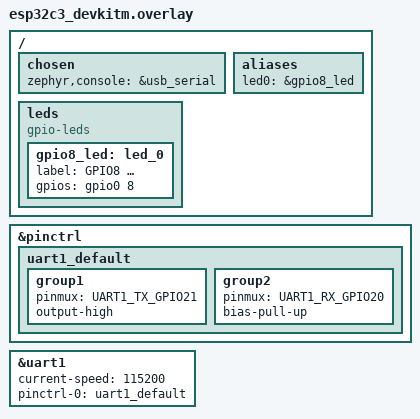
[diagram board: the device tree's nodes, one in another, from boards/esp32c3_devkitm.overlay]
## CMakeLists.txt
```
# SPDX-License-Identifier: Apache-2.0

cmake_minimum_required(VERSION 3.20.0)
find_package(Zephyr REQUIRED HINTS $ENV{ZEPHYR_BASE})
project(esp32_c3_gpio8_blinky)

target_sources(app PRIVATE
	src/main.c
)
```

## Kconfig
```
source "Kconfig.zephyr"

menu "ESP32-C3 OTA demo options"

config APP_BLINK_INTERVAL_MS
	int "GPIO8 blink interval in milliseconds"
	default 1000
	help
	  GPIO8 blink interval used to distinguish the factory image from the
	  OTA-updated application image.

endmenu
```

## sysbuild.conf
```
# Enable MCUboot so sysbuild produces a bootloader image and a signed application.
SB_CONFIG_BOOTLOADER_MCUBOOT=y
```

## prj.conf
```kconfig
# ESP32-C3-DevKitM 的 GPIO8 LED 闪灯配置。
CONFIG_GPIO=y

# 保持开发板默认 UART0 控制台可用，用于启动日志和 OTA 调试。
CONFIG_SERIAL=y
CONFIG_CONSOLE=y
CONFIG_UART_CONSOLE=y

CONFIG_LOG=y
CONFIG_LOG_MODE_IMMEDIATE=y
CONFIG_LOG_BACKEND_UART=y
CONFIG_LOG_DEFAULT_LEVEL=3

# 业务图片流使用独立 UART1，日志继续走 USB Serial/JTAG，避免污染 JPGU 数据。
CONFIG_UART_INTERRUPT_DRIVEN=y
CONFIG_RING_BUFFER=y

# BLE 外设同时提供小程序图片透传服务和 Zephyr MCUmgr/SMP OTA 服务。
CONFIG_BT=y
CONFIG_BT_PERIPHERAL=y
CONFIG_BT_DEVICE_NAME="E-Badge-C3"
CONFIG_BT_MAX_CONN=1
CONFIG_BT_L2CAP_TX_MTU=247
CONFIG_BT_BUF_ACL_RX_SIZE=251
CONFIG_BT_BUF_ACL_TX_SIZE=251
CONFIG_BT_BUF_ACL_TX_COUNT=12
CONFIG_BT_CONN_TX_MAX=12
CONFIG_BT_ATT_PREPARE_COUNT=4

CONFIG_REBOOT=y
CONFIG_FLASH=y
CONFIG_FLASH_MAP=y

# MCUboot + MCUmgr/SMP over BLE OTA。
CONFIG_BOOTLOADER_MCUBOOT=y
CONFIG_NET_BUF=y
CONFIG_ZCBOR=y
CONFIG_CRC=y
CONFIG_STREAM_FLASH=y
CONFIG_IMG_MANAGER=y
CONFIG_IMG_ERASE_PROGRESSIVELY=y
CONFIG_MCUMGR=y
CONFIG_MCUMGR_GRP_IMG=y
CONFIG_MCUMGR_GRP_IMG_VERBOSE_ERR=y
CONFIG_MCUMGR_GRP_OS=y
CONFIG_MCUMGR_GRP_OS_MCUMGR_PARAMS=y
CONFIG_MCUMGR_TRANSPORT_BT=y
CONFIG_MCUMGR_TRANSPORT_BT_PERM_RW=y
CONFIG_MCUMGR_TRANSPORT_BT_REASSEMBLY=y
CONFIG_MCUMGR_TRANSPORT_NETBUF_SIZE=1024
CONFIG_MCUMGR_TRANSPORT_NETBUF_COUNT=4
CONFIG_MCUMGR_TRANSPORT_WORKQUEUE_STACK_SIZE=4096
CONFIG_MAIN_STACK_SIZE=3072
CONFIG_SYSTEM_WORKQUEUE_STACK_SIZE=2048
```

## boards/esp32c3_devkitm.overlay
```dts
/* GPIO8 连接外部 LED，使用高电平点亮。 */
/ {
	chosen {
		/* ESP32-C3 USB Serial/JTAG：用于烧录后的启动日志输出。 */
		zephyr,console = &usb_serial;
	};

	aliases {
		led0 = &gpio8_led;
	};

	leds {
		compatible = "gpio-leds";

		gpio8_led: led_0 {
			label = "GPIO8 指示灯";
			gpios = <&gpio0 8 GPIO_ACTIVE_HIGH>;
		};
	};
};

&pinctrl {
	uart1_default: uart1_default {
		group1 {
			/* 业务串口 TX：ESP32C3 GPIO21 -> MCU RX。 */
			pinmux = <UART1_TX_GPIO21>;
			output-high;
		};

		group2 {
			/* 业务串口 RX：ESP32C3 GPIO20 <- MCU TX。 */
			pinmux = <UART1_RX_GPIO20>;
			bias-pull-up;
		};
	};
};

&uart1 {
	status = "okay";
	current-speed = <115200>;
	pinctrl-0 = <&uart1_default>;
	pinctrl-names = "default";
};
```

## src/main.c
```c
/*
 * SPDX-License-Identifier: Apache-2.0
 */

#include <zephyr/bluetooth/bluetooth.h>
#include <zephyr/bluetooth/conn.h>
#include <zephyr/bluetooth/gatt.h>
#include <zephyr/bluetooth/uuid.h>
#include <zephyr/dfu/mcuboot.h>
#include <zephyr/drivers/gpio.h>
#include <zephyr/drivers/uart.h>
#include <zephyr/kernel.h>
#include <zephyr/logging/log.h>
#include <zephyr/mgmt/mcumgr/transport/smp_bt.h>
#include <zephyr/sys/ring_buffer.h>
#include <zephyr/sys/util.h>

#include <errno.h>
#include <string.h>

#define BLINK_INTERVAL_MS CONFIG_APP_BLINK_INTERVAL_MS
#define BLE_DEVICE_NAME CONFIG_BT_DEVICE_NAME
#define BRIDGE_UART_NODE DT_NODELABEL(uart1)
#define STARTUP_WAIT_MS 2000
#define LED0_NODE DT_ALIAS(led0)
#define UART_TX_RING_SIZE 8192
#define UART_TX_CHUNK_SIZE 128
#define JPGU_ACK_LEN 13
#define JPGU_ACK_QUEUE_LEN 8
#define JPGU_MAGIC "JPGU"
#define JPGU_VERSION 0x01
#define JPGU_CMD_ACK 0x80
#define JPGU_CMD_NACK 0x81

LOG_MODULE_REGISTER(esp32c3_bridge, LOG_LEVEL_INF);

#if !DT_NODE_HAS_STATUS(LED0_NODE, okay)
#error "未定义 led0 别名；请检查板级 overlay"
#endif

#if !DT_NODE_HAS_STATUS(BRIDGE_UART_NODE, okay)
#error "未启用 uart1；请检查板级 overlay"
#endif

static const struct gpio_dt_spec led = GPIO_DT_SPEC_GET(LED0_NODE, gpios);
static const struct device *const bridge_uart = DEVICE_DT_GET(BRIDGE_UART_NODE);
static struct bt_conn *current_conn;
static bool notify_enabled;

RING_BUF_DECLARE(uart_tx_ring, UART_TX_RING_SIZE);
K_MUTEX_DEFINE(uart_tx_lock);
K_SEM_DEFINE(uart_tx_sem, 0, UINT_MAX);
K_MSGQ_DEFINE(jpgu_ack_msgq, JPGU_ACK_LEN, JPGU_ACK_QUEUE_LEN, 4);

static struct k_work notify_ack_work;

static struct bt_uuid_128 bridge_svc_uuid =
	BT_UUID_INIT_128(BT_UUID_128_ENCODE(0x6e400001, 0xb5a3, 0xf393, 0xe0a9,
					    0xe50e24dcca9e));
static struct bt_uuid_128 bridge_rx_uuid =
	BT_UUID_INIT_128(BT_UUID_128_ENCODE(0x6e400002, 0xb5a3, 0xf393, 0xe0a9,
					    0xe50e24dcca9e));
static struct bt_uuid_128 bridge_tx_uuid =
	BT_UUID_INIT_128(BT_UUID_128_ENCODE(0x6e400003, 0xb5a3, 0xf393, 0xe0a9,
					    0xe50e24dcca9e));

static ssize_t bridge_rx_write(struct bt_conn *conn, const struct bt_gatt_attr *attr,
			       const void *buf, uint16_t len, uint16_t offset,
			       uint8_t flags);
static void bridge_tx_ccc_changed(const struct bt_gatt_attr *attr, uint16_t value);

BT_GATT_SERVICE_DEFINE(bridge_svc,
	BT_GATT_PRIMARY_SERVICE(&bridge_svc_uuid),
	BT_GATT_CHARACTERISTIC(&bridge_rx_uuid.uuid,
			       BT_GATT_CHRC_WRITE | BT_GATT_CHRC_WRITE_WITHOUT_RESP,
			       BT_GATT_PERM_WRITE, NULL, bridge_rx_write, NULL),
	BT_GATT_CHARACTERISTIC(&bridge_tx_uuid.uuid, BT_GATT_CHRC_NOTIFY,
			       BT_GATT_PERM_NONE, NULL, NULL, NULL),
	BT_GATT_CCC(bridge_tx_ccc_changed, BT_GATT_PERM_READ | BT_GATT_PERM_WRITE),
);

static const struct bt_data ad[] = {
	BT_DATA_BYTES(BT_DATA_FLAGS, BT_LE_AD_GENERAL | BT_LE_AD_NO_BREDR),
	BT_DATA_BYTES(BT_DATA_UUID128_ALL, BT_UUID_128_ENCODE(0x6e400001, 0xb5a3,
							      0xf393, 0xe0a9,
							      0xe50e24dcca9e)),
};

static const struct bt_data sd[] = {
	BT_DATA(BT_DATA_NAME_COMPLETE, BLE_DEVICE_NAME, sizeof(BLE_DEVICE_NAME) - 1),
	BT_DATA_BYTES(BT_DATA_UUID128_ALL, SMP_BT_SVC_UUID_VAL),
};

static void start_advertising(void)
{
	int ret = bt_le_adv_start(BT_LE_ADV_CONN_FAST_1, ad, ARRAY_SIZE(ad), sd,
		ARRAY_SIZE(sd));

	if (ret == -EALREADY) {
		LOG_INF("BLE 广播已经启动");
		return;
	}
	if (ret != 0) {
		LOG_ERR("启动 BLE 广播失败：%d", ret);
		return;
	}

	LOG_INF("BLE 图片桥接广播已启动，名称：%s", BLE_DEVICE_NAME);
	LOG_INF("小程序服务 UUID：6E400001-B5A3-F393-E0A9-E50E24DCCA9E");
	LOG_INF("SMP OTA 服务 UUID：8D53DC1D-1DB7-4CD3-868B-8A527460AA84");
}

static void restart_advertising_work_handler(struct k_work *work)
{
	ARG_UNUSED(work);
	start_advertising();
}

K_WORK_DELAYABLE_DEFINE(advertising_restart_work, restart_advertising_work_handler);

static void on_connected(struct bt_conn *conn, uint8_t err)
{
	if (err != 0) {
		LOG_WRN("BLE 连接失败：%u", err);
		k_work_reschedule(&advertising_restart_work, K_MSEC(200));
		return;
	}

	current_conn = bt_conn_ref(conn);
	notify_enabled = false;
	LOG_INF("BLE 已连接");
}

static void on_disconnected(struct bt_conn *conn, uint8_t reason)
{
	if (current_conn != NULL) {
		bt_conn_unref(current_conn);
		current_conn = NULL;
	}
	notify_enabled = false;

	k_mutex_lock(&uart_tx_lock, K_FOREVER);
	ring_buf_reset(&uart_tx_ring);
	k_mutex_unlock(&uart_tx_lock);
	k_msgq_purge(&jpgu_ack_msgq);

	LOG_INF("BLE 已断开：%u", reason);
	k_work_reschedule(&advertising_restart_work, K_MSEC(200));
}

BT_CONN_CB_DEFINE(connection_callbacks) = {
	.connected = on_connected,
	.disconnected = on_disconnected,
};

static void bridge_tx_ccc_changed(const struct bt_gatt_attr *attr, uint16_t value)
{
	ARG_UNUSED(attr);

	notify_enabled = (value == BT_GATT_CCC_NOTIFY);
	LOG_INF("小程序通知通道%s", notify_enabled ? "已开启" : "已关闭");
}

static ssize_t bridge_rx_write(struct bt_conn *conn, const struct bt_gatt_attr *attr,
			       const void *buf, uint16_t len, uint16_t offset,
			       uint8_t flags)
{
	uint32_t written;

	ARG_UNUSED(conn);
	ARG_UNUSED(attr);
	ARG_UNUSED(flags);

	if (offset != 0U) {
		return BT_GATT_ERR(BT_ATT_ERR_INVALID_OFFSET);
	}

	k_mutex_lock(&uart_tx_lock, K_FOREVER);
	written = ring_buf_put(&uart_tx_ring, buf, len);
	k_mutex_unlock(&uart_tx_lock);

	if (written != len) {
		LOG_WRN("UART 发送队列空间不足：收到 %u 字节，仅入队 %u 字节", len, written);
		return BT_GATT_ERR(BT_ATT_ERR_INSUFFICIENT_RESOURCES);
	}

	k_sem_give(&uart_tx_sem);
	LOG_DBG("BLE 写入 %u 字节，已加入 UART 队列", len);
	return len;
}

static bool is_valid_jpgu_ack(const uint8_t frame[JPGU_ACK_LEN])
{
	return memcmp(frame, JPGU_MAGIC, strlen(JPGU_MAGIC)) == 0 &&
	       frame[4] == JPGU_VERSION &&
	       (frame[5] == JPGU_CMD_ACK || frame[5] == JPGU_CMD_NACK);
}

static void uart_ack_scanner_push(uint8_t byte)
{
	static uint8_t frame[JPGU_ACK_LEN];
	static uint8_t pos;

	if (pos < strlen(JPGU_MAGIC)) {
		if (byte == JPGU_MAGIC[pos]) {
			frame[pos++] = byte;
			return;
		}

		pos = (byte == JPGU_MAGIC[0]) ? 1U : 0U;
		frame[0] = byte;
		return;
	}

	frame[pos++] = byte;

	if (pos < JPGU_ACK_LEN) {
		return;
	}

	if (is_valid_jpgu_ack(frame)) {
		if (k_msgq_put(&jpgu_ack_msgq, frame, K_NO_WAIT) != 0) {
			LOG_WRN("ACK 通知队列已满，丢弃一帧 MCU 回复");
		} else {
			k_work_submit(&notify_ack_work);
		}
	} else {
		LOG_WRN("收到无效 JPGU ACK/NACK 帧，已丢弃");
	}

	pos = 0U;
}

static void bridge_uart_isr(const struct device *dev, void *user_data)
{
	uint8_t rx_buf[32];

	ARG_UNUSED(user_data);

	while (uart_irq_update(dev) != 0 && uart_irq_is_pending(dev) != 0) {
		if (uart_irq_rx_ready(dev) == 0) {
			continue;
		}

		int read_len = uart_fifo_read(dev, rx_buf, sizeof(rx_buf));

		for (int i = 0; i < read_len; i++) {
			uart_ack_scanner_push(rx_buf[i]);
		}
	}
}

static void notify_ack_work_handler(struct k_work *work)
{
	uint8_t frame[JPGU_ACK_LEN];

	ARG_UNUSED(work);

	while (k_msgq_get(&jpgu_ack_msgq, frame, K_NO_WAIT) == 0) {
		if (current_conn == NULL || !notify_enabled) {
			LOG_WRN("小程序通知通道未就绪，丢弃一帧 MCU 回复");
			continue;
		}

		int ret = bt_gatt_notify(current_conn, &bridge_svc.attrs[4], frame,
					 sizeof(frame));

		if (ret != 0) {
			LOG_WRN("通知小程序 ACK/NACK 失败：%d", ret);
		} else {
			LOG_DBG("已通知小程序 JPGU ACK/NACK cmd=0x%02x status=%u", frame[5],
				frame[12]);
		}
	}
}

static void uart_tx_thread(void *arg1, void *arg2, void *arg3)
{
	uint8_t tx_buf[UART_TX_CHUNK_SIZE];

	ARG_UNUSED(arg1);
	ARG_UNUSED(arg2);
	ARG_UNUSED(arg3);

	while (true) {
		k_sem_take(&uart_tx_sem, K_FOREVER);

		while (true) {
			uint32_t len;

			k_mutex_lock(&uart_tx_lock, K_FOREVER);
			len = ring_buf_get(&uart_tx_ring, tx_buf, sizeof(tx_buf));
			k_mutex_unlock(&uart_tx_lock);

			if (len == 0U) {
				break;
			}

			for (uint32_t i = 0; i < len; i++) {
				uart_poll_out(bridge_uart, tx_buf[i]);
			}
		}
	}
}

K_THREAD_DEFINE(uart_tx_thread_id, 1536, uart_tx_thread, NULL, NULL, NULL, 7, 0, 0);

static void confirm_running_image(void)
{
	int ret;

	if (boot_is_img_confirmed()) {
		LOG_INF("当前 MCUboot 镜像已确认");
		return;
	}

	ret = boot_write_img_confirmed();
	if (ret == 0) {
		LOG_INF("当前 MCUboot 镜像确认成功");
	} else {
		LOG_WRN("当前 MCUboot 镜像确认失败：%d", ret);
	}
}

static int init_uart_bridge(void)
{
	int ret;

	if (!device_is_ready(bridge_uart)) {
		LOG_ERR("业务 UART1 未就绪");
		return -ENODEV;
	}

	k_work_init(&notify_ack_work, notify_ack_work_handler);
	ret = uart_irq_callback_user_data_set(bridge_uart, bridge_uart_isr, NULL);
	if (ret != 0) {
		LOG_ERR("设置业务 UART1 中断回调失败：%d", ret);
		return ret;
	}
	uart_irq_rx_enable(bridge_uart);

	LOG_INF("业务 UART1 已启动：GPIO21 TX、GPIO20 RX、115200 8N1");
	return 0;
}

int main(void)
{
	int ret;

	k_msleep(STARTUP_WAIT_MS);
	LOG_INF("应用启动，开始初始化 GPIO8 状态灯");

	if (!gpio_is_ready_dt(&led)) {
		LOG_ERR("GPIO8 控制器未就绪，应用停止运行");
		return 0;
	}

	ret = gpio_pin_configure_dt(&led, GPIO_OUTPUT_INACTIVE);
	if (ret < 0) {
		LOG_ERR("GPIO8 配置为输出失败：%d", ret);
		return 0;
	}

	LOG_INF("GPIO8 初始化完成，开始每 %d ms 翻转一次", BLINK_INTERVAL_MS);
	confirm_running_image();

	ret = init_uart_bridge();
	if (ret != 0) {
		LOG_ERR("业务 UART 桥接初始化失败：%d", ret);
		return 0;
	}

	ret = bt_enable(NULL);
	if (ret != 0) {
		LOG_ERR("蓝牙控制器初始化失败：%d", ret);
	} else {
		start_advertising();
	}

	while (true) {
		ret = gpio_pin_toggle_dt(&led);
		if (ret < 0) {
			LOG_ERR("GPIO8 翻转失败：%d，应用停止运行", ret);
			return 0;
		}

		k_msleep(BLINK_INTERVAL_MS);
	}
}
```

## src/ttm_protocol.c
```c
/* SPDX-License-Identifier: Apache-2.0 */
#include "ttm_protocol.h"

#include <stdio.h>
#include <string.h>

static void send_bytes(const struct ttm_protocol *protocol, const uint8_t *data, size_t len)
{
	protocol->port->uart_send(protocol->port->context, data, len);
}

static void send_text(const struct ttm_protocol *protocol, const char *text)
{
	send_bytes(protocol, (const uint8_t *)text, strlen(text));
}

static void send_ok(const struct ttm_protocol *protocol)
{
	send_text(protocol, "TTM:OK\r\n");
}

static void send_error(const struct ttm_protocol *protocol)
{
	send_text(protocol, "TTM:ERP\r\n");
}

static bool is_idle(const struct ttm_protocol *protocol)
{
	return !protocol->port->connected(protocol->port->context);
}

static bool is_allowed(uint32_t value, const uint32_t *values, size_t count)
{
	for (size_t i = 0; i < count; i++) {
		if (value == values[i]) {
			return true;
		}
	}

	return false;
}

static int hex_value(char character)
{
	if (character >= '0' && character <= '9') {
		return character - '0';
	}
	if (character >= 'A' && character <= 'F') {
		return character - 'A' + 10;
	}
	if (character >= 'a' && character <= 'f') {
		return character - 'a' + 10;
	}

	return -1;
}

static bool parse_hex_byte(const char *text, uint8_t *value)
{
	int high = hex_value(text[0]);
	int low = hex_value(text[1]);

	if (high < 0 || low < 0) {
		return false;
	}
	*value = (uint8_t)((high << 4) | low);
	return true;
}

static bool parse_product_id(const char *text, uint16_t *product_id)
{
	uint8_t high;
	uint8_t low;

	if (strlen(text) != 4 || !parse_hex_byte(text, &high) ||
	    !parse_hex_byte(text + 2, &low)) {
		return false;
	}
	*product_id = ((uint16_t)high << 8) | low;
	return true;
}

static bool parse_mac(const char *text, uint8_t mac[6])
{
	if (strlen(text) != 12) {
		return false;
	}

	/* AT 命令按正常显示顺序输入，Zephyr 地址数组按小端顺序保存。 */
	for (size_t i = 0; i < 6; i++) {
		if (!parse_hex_byte(text + i * 2, &mac[5 - i])) {
			return false;
		}
	}

	return true;
}

static int apply_advertising_config(struct ttm_protocol *protocol,
	const struct ttm_config *candidate)
{
	int ret = protocol->port->restart_advertising(protocol->port->context, candidate);

	if (ret == 0) {
		*protocol->config = *candidate;
		protocol->port->save_config(protocol->port->context, protocol->config);
	}

	return ret;
}

static void reply_name(const struct ttm_protocol *protocol)
{
	char reply[sizeof(protocol->config->name) + 10];

	snprintf(reply, sizeof(reply), "TTM:REN-%s\r\n", protocol->config->name);
	send_text(protocol, reply);
}

static void reply_mac(const struct ttm_protocol *protocol)
{
	char reply[32];

	snprintf(reply, sizeof(reply), "TTM:MAC-%02X%02X%02X%02X%02X%02X\r\n",
		 protocol->config->mac[5], protocol->config->mac[4], protocol->config->mac[3],
		 protocol->config->mac[2], protocol->config->mac[1], protocol->config->mac[0]);
	send_text(protocol, reply);
}

static void reply_add(const struct ttm_protocol *protocol)
{
	static const char prefix[] = "TTM:ADD-";

	send_text(protocol, prefix);
	send_bytes(protocol, protocol->config->add_data, protocol->config->add_len);
	send_text(protocol, "\r\n");
}

void ttm_protocol_defaults(struct ttm_config *config, const uint8_t mac[6])
{
	memset(config, 0, sizeof(*config));
	config->baudrate = 115200;
	config->tx_power_dbm = 4;
	/* 原始模块出厂广播间隔为 20 ms。 */
	config->adv_interval_ms = 20;
	memcpy(config->mac, mac, sizeof(config->mac));
	snprintf(config->name, sizeof(config->name), "LSD-BLE-%02X%02X%02X",
		 mac[2], mac[1], mac[0]);
}

void ttm_protocol_init(struct ttm_protocol *protocol, struct ttm_config *config,
	const struct ttm_port *port)
{
	protocol->config = config;
	protocol->port = port;
}

void ttm_protocol_on_ble(struct ttm_protocol *protocol, const uint8_t *data, size_t len)
{
	protocol->port->uart_send(protocol->port->context, data, len);
}

void ttm_protocol_on_uart(struct ttm_protocol *protocol, const uint8_t *data, size_t len)
{
	char command[64];
	uint32_t value;
	int used;

	if (len < 3 || memcmp(data, "TTM", 3) != 0) {
		protocol->port->ble_send(protocol->port->context, data, len);
		return;
	}
	if (len >= sizeof(command)) {
		send_error(protocol);
		return;
	}

	memcpy(command, data, len);
	command[len] = '\0';
	while (len > 0 && (command[len - 1] == '\r' || command[len - 1] == '\n')) {
		command[--len] = '\0';
	}
	/* 所有 AT 指令均先回显，再给出执行结果。 */
	send_bytes(protocol, (const uint8_t *)command, len);
	/* 原始协议的 PID 参数是两个二进制字节，保留这一兼容格式。 */
	if (len == 10 && memcmp(data, "TTM:PID-", 8) == 0) {
		struct ttm_config candidate = *protocol->config;

		if (!is_idle(protocol)) {
			send_error(protocol);
			return;
		}
		candidate.product_id = (uint16_t)data[8] | ((uint16_t)data[9] << 8);
		if (apply_advertising_config(protocol, &candidate) != 0) {
			send_error(protocol);
			return;
		}
		send_ok(protocol);
		return;
	}

	if (strcmp(command, "TTM:VID-?") == 0) {
		send_text(protocol, "TTM:VID-LSD_BLE_5.0\r\n");
		return;
	}
	if (strcmp(command, "TTM:REV-?") == 0) {
		send_text(protocol, "TTM:REV-V2.1\r\n");
		return;
	}
	if (strcmp(command, "TTM:REN-?") == 0) {
		reply_name(protocol);
		return;
	}
	if (strcmp(command, "TTM:MAC-?") == 0) {
		reply_mac(protocol);
		return;
	}
	if (strcmp(command, "TTM:ADD-?") == 0) {
		reply_add(protocol);
		return;
	}
	if (strcmp(command, "TTM:RST-SYSTEMRESET") == 0) {
		send_ok(protocol);
		protocol->port->reset_system(protocol->port->context);
		return;
	}

	if (sscanf(command, "TTM:BPS-%u%n", &value, &used) == 1 && command[used] == '\0') {
		static const uint32_t allowed[] = {2400, 4800, 9600, 14400, 19200,
			28800, 38400, 57600, 76800, 115200};

		if (!is_allowed(value, allowed, sizeof(allowed) / sizeof(allowed[0]))) {
			send_error(protocol);
			return;
		}
		/* 先以旧波特率发送确认，再切换到新波特率。 */
		send_ok(protocol);
		protocol->config->baudrate = value;
		protocol->port->set_baudrate(protocol->port->context, value);
		return;
	}

	if (sscanf(command, "TTM:CDL-%ums%n", &value, &used) == 1 && command[used] == '\0') {
		static const uint32_t allowed[] = {0, 2, 5, 10, 15, 20, 25};

		if (!is_idle(protocol) || !is_allowed(value, allowed, sizeof(allowed) / sizeof(allowed[0]))) {
			send_error(protocol);
			return;
		}
		protocol->config->delay_ms = value;
		protocol->port->save_config(protocol->port->context, protocol->config);
		send_ok(protocol);
		return;
	}

	if (strncmp(command, "TTM:TPL-", 8) == 0) {
		const char *power = command + 8;
		int8_t dbm;

		if (strcmp(power, "+4") == 0) {
			dbm = 4;
		} else if (strcmp(power, "0") == 0) {
			dbm = 0;
		} else if (strcmp(power, "-6") == 0) {
			dbm = -6;
		} else if (strcmp(power, "-23") == 0) {
			dbm = -23;
		} else {
			send_error(protocol);
			return;
		}
		if (protocol->port->set_tx_power(protocol->port->context, dbm) != 0) {
			send_error(protocol);
			return;
		}
		protocol->config->tx_power_dbm = dbm;
		if (protocol->port->connected(protocol->port->context)) {
			protocol->port->disconnect_ble(protocol->port->context);
		}
		send_ok(protocol);
		return;
	}

	if (sscanf(command, "TTM:ADP-%u%n", &value, &used) == 1 && command[used] == '\0') {
		static const uint32_t allowed[] = {2, 5, 10, 15, 20, 25, 30, 40, 50};
		struct ttm_config candidate = *protocol->config;

		if (!is_idle(protocol) || !is_allowed(value, allowed, sizeof(allowed) / sizeof(allowed[0]))) {
			send_error(protocol);
			return;
		}
		candidate.adv_interval_ms = value * 100;
		if (apply_advertising_config(protocol, &candidate) != 0) {
			send_error(protocol);
			return;
		}
		send_ok(protocol);
		return;
	}

	if (strncmp(command, "TTM:PID-", 8) == 0) {
		struct ttm_config candidate = *protocol->config;

		if (!is_idle(protocol) || !parse_product_id(command + 8, &candidate.product_id)) {
			send_error(protocol);
			return;
		}
		if (apply_advertising_config(protocol, &candidate) != 0) {
			send_error(protocol);
			return;
		}
		send_ok(protocol);
		return;
	}

	if (strncmp(command, "TTM:REN-", 8) == 0) {
		const char *name = command + 8;
		struct ttm_config candidate = *protocol->config;

		if (!is_idle(protocol) || strlen(name) == 0 || strlen(name) > TTM_NAME_MAX_LEN) {
			send_error(protocol);
			return;
		}
		strcpy(candidate.name, name);
		if (apply_advertising_config(protocol, &candidate) != 0) {
			send_error(protocol);
			return;
		}
		return send_ok(protocol);
	}

	if (strncmp(command, "TTM:MAC-", 8) == 0) {
		struct ttm_config candidate = *protocol->config;

		if (!is_idle(protocol) || !parse_mac(command + 8, candidate.mac)) {
			send_error(protocol);
			return;
		}
		candidate.custom_mac = true;
		if (protocol->port->set_mac(protocol->port->context, candidate.mac) != 0) {
			send_error(protocol);
			return;
		}
		*protocol->config = candidate;
		protocol->port->save_config(protocol->port->context, protocol->config);
		send_ok(protocol);
		return;
	}

	if (strncmp(command, "TTM:ADD-", 8) == 0) {
		const char *add = command + 8;
		size_t add_len = strlen(add);
		struct ttm_config candidate = *protocol->config;

		if (!is_idle(protocol) || add_len == 0 || add_len > TTM_ADD_MAX_LEN) {
			send_error(protocol);
			return;
		}
		memcpy(candidate.add_data, add, add_len);
		candidate.add_len = add_len;
		if (apply_advertising_config(protocol, &candidate) != 0) {
			send_error(protocol);
			return;
		}
		send_ok(protocol);
		return;
	}

	if (sscanf(command, "TTM:CIT-%ums%n", &value, &used) == 1 && command[used] == '\0') {
		static const uint32_t allowed[] = {20, 50, 100, 200, 300, 400, 500,
			1000, 1500, 2000};

		if (!protocol->port->connected(protocol->port->context) || !is_allowed(value, allowed, sizeof(allowed) / sizeof(allowed[0]))) {
			send_error(protocol);
			return;
		}
		if (protocol->port->set_connection_interval(protocol->port->context, value) != 0) {
			send_text(protocol, "TTM:TIMEOUT\r\n");
			return;
		}
		send_ok(protocol);
		return;
	}

	send_error(protocol);
}
```

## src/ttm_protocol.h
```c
/* SPDX-License-Identifier: Apache-2.0 */
#ifndef TTM_PROTOCOL_H
#define TTM_PROTOCOL_H

#include <stdbool.h>
#include <stddef.h>
#include <stdint.h>

#define TTM_NAME_MAX_LEN 20
#define TTM_ADD_MAX_LEN 16

/* 此文件仅定义应用协议，不依赖 Zephyr 或任何芯片 SDK。 */
struct ttm_config {
	uint32_t baudrate;
	uint16_t delay_ms;
	int8_t tx_power_dbm;
	uint16_t adv_interval_ms;
	uint16_t product_id;
	char name[TTM_NAME_MAX_LEN + 1];
	uint8_t mac[6];
	bool custom_mac;
	uint8_t add_data[TTM_ADD_MAX_LEN];
	uint8_t add_len;
};

/* 后续移植时由新平台实现这些回调。 */
struct ttm_port {
	void *context;
	void (*uart_send)(void *context, const uint8_t *data, size_t len);
	void (*ble_send)(void *context, const uint8_t *data, size_t len);
	bool (*connected)(void *context);
	int (*set_baudrate)(void *context, uint32_t baudrate);
	int (*set_tx_power)(void *context, int8_t dbm);
	int (*restart_advertising)(void *context, const struct ttm_config *config);
	int (*set_connection_interval)(void *context, uint16_t interval_ms);
	int (*set_mac)(void *context, const uint8_t mac[6]);
	void (*disconnect_ble)(void *context);
	void (*save_config)(void *context, const struct ttm_config *config);
	void (*reset_system)(void *context);
};

/* 每个协议实例独立保存状态，可被不同平台或测试程序同时使用。 */
struct ttm_protocol {
	struct ttm_config *config;
	const struct ttm_port *port;
};

void ttm_protocol_defaults(struct ttm_config *config, const uint8_t mac[6]);
void ttm_protocol_init(struct ttm_protocol *protocol, struct ttm_config *config,
	const struct ttm_port *port);
void ttm_protocol_on_uart(struct ttm_protocol *protocol, const uint8_t *data, size_t len);
void ttm_protocol_on_ble(struct ttm_protocol *protocol, const uint8_t *data, size_t len);

#endif
```
